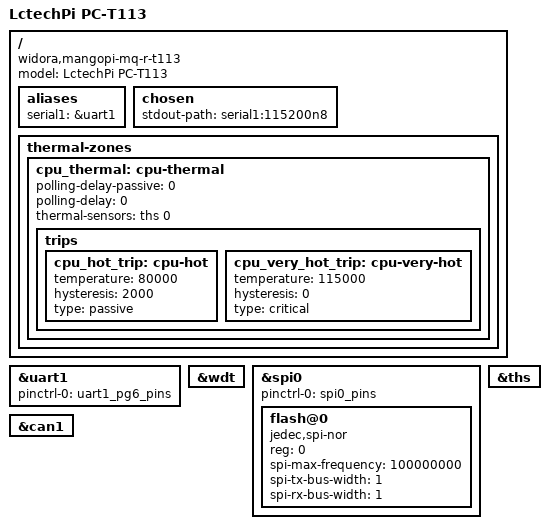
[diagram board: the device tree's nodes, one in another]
// SPDX-License-Identifier: (GPL-2.0+ OR MIT)
// Copyright (C) 2024 Maksim Kiselev <bigunclemax@gmail.com>.

/dts-v1/;

#include "sun8i-t113s-mangopi-mq-r-t113.dts"

/ {
	model = "LctechPi PC-T113";
	compatible = "widora,mangopi-mq-r-t113", "allwinner,sun8i-t113s";

	aliases {
		serial1 = &uart1;
	};

	chosen {
		stdout-path = "serial1:115200n8";
	};

	thermal-zones {
		cpu_thermal: cpu-thermal {
			polling-delay-passive = <0>;
			polling-delay = <0>;
			thermal-sensors = <&ths 0>;

			trips {
				cpu_hot_trip: cpu-hot {
					temperature = <80000>;
					hysteresis = <2000>;
					type = "passive";
				};

				cpu_very_hot_trip: cpu-very-hot {
					temperature = <115000>;
					hysteresis = <0>;
					type = "critical";
				};
			};
		};
	};
};

&uart1 {
	pinctrl-names = "default";
	pinctrl-0 = <&uart1_pg6_pins>;
	status = "okay";
};

&wdt {
	status = "okay";
};

&spi0 {
	pinctrl-names = "default";
	pinctrl-0 = <&spi0_pins>;
	status = "okay";

	flash@0 { /* W25Q128JVEI */
		compatible = "jedec,spi-nor";
		reg = <0>;
		spi-max-frequency = <100000000>; /* Up to 133 MHz */
		spi-tx-bus-width = <1>;
		spi-rx-bus-width = <1>;
	};

};

&ths {
	status = "okay";
};

&can1 {
	status = "okay";
};
